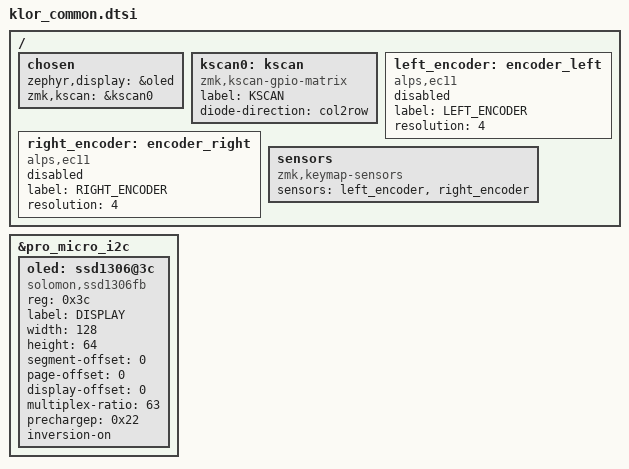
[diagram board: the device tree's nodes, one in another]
/*
 * Copyright (c) 2022 The ZMK Contributors
 *
 * SPDX-License-Identifier: MIT
 */

#include <dt-bindings/zmk/matrix_transform.h>

/ {
	chosen {
		zephyr,display = &oled;
		zmk,kscan = &kscan0;
		/* zmk,matrix_transform intentionally not set here — klor.dtsi sets
		 * zmk,physical-layout instead (required for ZMK Studio), which carries
		 * its own `transform` reference. Setting both makes ZMK ignore the
		 * physical layout and fall back to the raw transform, which then fails
		 * Studio's build-time check. */
	};

	kscan0: kscan {
		compatible = "zmk,kscan-gpio-matrix";
		label = "KSCAN";

		diode-direction = "col2row";		
	};

	left_encoder: encoder_left {
		compatible = "alps,ec11";
		label = "LEFT_ENCODER";
		resolution = <4>;
		status = "disabled";
	};

	right_encoder: encoder_right {
		compatible = "alps,ec11";
		label = "RIGHT_ENCODER";
		resolution = <4>;
		status = "disabled";
	};

	sensors {
		compatible = "zmk,keymap-sensors";
		sensors = <&left_encoder &right_encoder>;
	};

	// TODO: RGB node(s)
};

&pro_micro_i2c {
	status = "okay";

	oled: ssd1306@3c {
		compatible = "solomon,ssd1306fb";
		reg = <0x3c>;
		label = "DISPLAY";
		width = <128>;
		height = <64>;
		segment-offset = <0>;
		page-offset = <0>;
		display-offset = <0>;
		multiplex-ratio = <63>;
		prechargep = <0x22>;
		/* Panel shows white bg/black fg by default -- code explicitly sets
		 * black bg/white fg (klor_status_screen.c, klor_widgets_util.c) and
		 * CONFIG_ZMK_DISPLAY_INVERT (klor_left.conf) only affects LVGL's
		 * mono theme color choice, not the physical controller, confirmed
		 * via zmkfirmware/zmk source search -- this SSD1306 devicetree
		 * property is the actual hardware polarity flip.
		 */
		inversion-on;
	};
};
